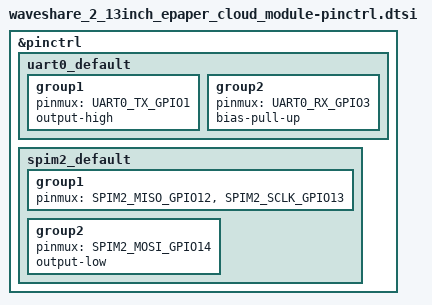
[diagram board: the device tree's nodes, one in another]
/*
 * Copyright (c) 2022 Espressif Systems (Shanghai) Co., Ltd.
 *
 * SPDX-License-Identifier: Apache-2.0
 */

#include <zephyr/dt-bindings/pinctrl/esp-pinctrl-common.h>
#include <dt-bindings/pinctrl/esp32-pinctrl.h>
#include <zephyr/dt-bindings/pinctrl/esp32-gpio-sigmap.h>

&pinctrl {
	uart0_default: uart0_default {
		group1 {
			pinmux = <UART0_TX_GPIO1>;
			output-high;
		};
		group2 {
			pinmux = <UART0_RX_GPIO3>;
			bias-pull-up;
		};
	};

	spim2_default: spim2_default {
		group1 {
			pinmux = <SPIM2_MISO_GPIO12>,
				<SPIM2_SCLK_GPIO13>;
		};
		group2 {
			pinmux = <SPIM2_MOSI_GPIO14>;
			output-low;
		};
	};

};
